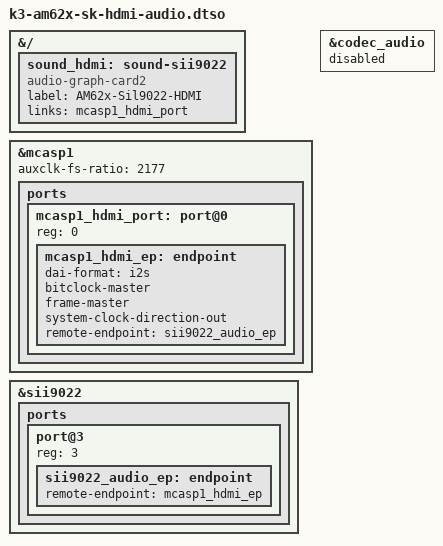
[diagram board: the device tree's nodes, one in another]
// SPDX-License-Identifier: GPL-2.0-only OR MIT
/**
 * Audio playback via HDMI for AM625-SK and AM62-LP SK.
 *
 * Links:
 * AM625 SK: https://www.ti.com/tool/SK-AM62
 * AM62-LP SK: https://www.ti.com/tool/SK-AM62-LP
 *
 * Copyright (C) 2023-2024 Texas Instruments Incorporated - https://www.ti.com/
 */

/dts-v1/;
/plugin/;

&{/} {
	sound_hdmi: sound-sii9022 {
		compatible = "audio-graph-card2";
		label = "AM62x-Sil9022-HDMI";
		links = <&mcasp1_hdmi_port>;
	};
};

&mcasp1 {
	auxclk-fs-ratio = <2177>;

	ports {
		#address-cells = <1>;
		#size-cells = <0>;

		mcasp1_hdmi_port: port@0 {
			reg = <0>;

			mcasp1_hdmi_ep: endpoint {
				dai-format = "i2s";
				bitclock-master;
				frame-master;
				system-clock-direction-out;
				remote-endpoint = <&sii9022_audio_ep>;
			};
		};
	};
};

&sii9022 {
	ports {
		#address-cells = <1>;
		#size-cells = <0>;

		port@3 {
			reg = <3>;

			sii9022_audio_ep: endpoint {
				remote-endpoint = <&mcasp1_hdmi_ep>;
			};
		};
	};
};

&codec_audio {
	status = "disabled";
};
